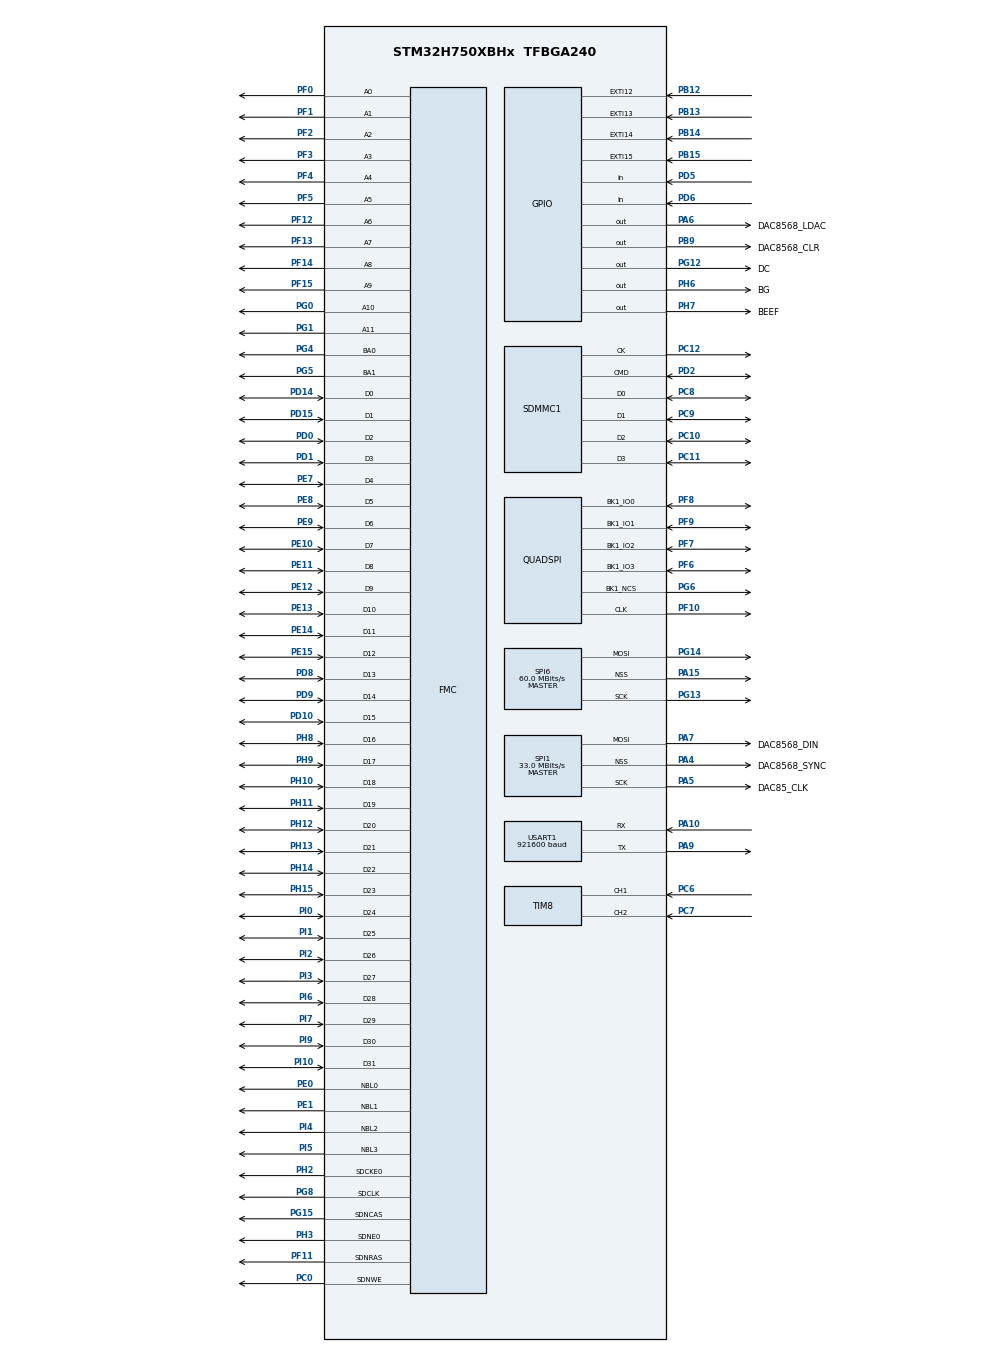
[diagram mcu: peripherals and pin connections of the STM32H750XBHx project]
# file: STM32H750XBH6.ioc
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CORTEX_M7.AccessPermission-Cortex_Memory_Protection_Unit_Region0_Settings=MPU_REGION_FULL_ACCESS
CORTEX_M7.AccessPermission-Cortex_Memory_Protection_Unit_Region1_Settings=MPU_REGION_FULL_ACCESS
CORTEX_M7.BaseAddress-Cortex_Memory_Protection_Unit_Region0_Settings=0xC0000000
CORTEX_M7.BaseAddress-Cortex_Memory_Protection_Unit_Region1_Settings=0x24000000
CORTEX_M7.CPU_DCache=Enabled
CORTEX_M7.CPU_ICache=Enabled
CORTEX_M7.Enable-Cortex_Memory_Protection_Unit_Region0_Settings=MPU_REGION_ENABLE
CORTEX_M7.Enable-Cortex_Memory_Protection_Unit_Region1_Settings=MPU_REGION_ENABLE
CORTEX_M7.IsBufferable-Cortex_Memory_Protection_Unit_Region0_Settings=MPU_ACCESS_NOT_BUFFERABLE
CORTEX_M7.IsBufferable-Cortex_Memory_Protection_Unit_Region1_Settings=MPU_ACCESS_BUFFERABLE
CORTEX_M7.IsCacheable-Cortex_Memory_Protection_Unit_Region0_Settings=MPU_ACCESS_CACHEABLE
CORTEX_M7.IsCacheable-Cortex_Memory_Protection_Unit_Region1_Settings=MPU_ACCESS_CACHEABLE
CORTEX_M7.IsShareable-Cortex_Memory_Protection_Unit_Region1_Settings=MPU_ACCESS_SHAREABLE
CORTEX_M7.MPU_Control=MPU_PRIVILEGED_DEFAULT
CORTEX_M7.Size-Cortex_Memory_Protection_Unit_Region0_Settings=MPU_REGION_SIZE_16MB
CORTEX_M7.Size-Cortex_Memory_Protection_Unit_Region1_Settings=MPU_REGION_SIZE_512KB
CORTEX_M7.TypeExtField-Cortex_Memory_Protection_Unit_Region1_Settings=MPU_TEX_LEVEL1
DMA2D.ColorMode=DMA2D_OUTPUT_RGB565
Dma.Request0=USART1_RX
Dma.Request1=USART1_TX
Dma.Request2=SPI1_TX
Dma.SPI1_TX.2.Direction=DMA_MEMORY_TO_PERIPH
Dma.SPI1_TX.2.EventEnable=DISABLE
Dma.SPI1_TX.2.FIFOMode=DMA_FIFOMODE_DISABLE
Dma.SPI1_TX.2.Instance=DMA1_Stream4
Dma.SPI1_TX.2.MemDataAlignment=DMA_MDATAALIGN_WORD
Dma.SPI1_TX.2.MemInc=DMA_MINC_ENABLE
Dma.SPI1_TX.2.Mode=DMA_CIRCULAR
Dma.SPI1_TX.2.PeriphDataAlignment=DMA_PDATAALIGN_WORD
Dma.SPI1_TX.2.PeriphInc=DMA_PINC_DISABLE
Dma.SPI1_TX.2.Polarity=HAL_DMAMUX_REQ_GEN_RISING
Dma.SPI1_TX.2.Priority=DMA_PRIORITY_HIGH
Dma.SPI1_TX.2.RequestNumber=1
Dma.SPI1_TX.2.SignalID=NONE
Dma.SPI1_TX.2.SyncEnable=DISABLE
Dma.SPI1_TX.2.SyncPolarity=HAL_DMAMUX_SYNC_NO_EVENT
Dma.SPI1_TX.2.SyncRequestNumber=1
Dma.SPI1_TX.2.SyncSignalID=NONE
Dma.USART1_RX.0.Direction=DMA_PERIPH_TO_MEMORY
Dma.USART1_RX.0.EventEnable=DISABLE
Dma.USART1_RX.0.FIFOMode=DMA_FIFOMODE_DISABLE
Dma.USART1_RX.0.Instance=DMA1_Stream0
Dma.USART1_RX.0.MemDataAlignment=DMA_MDATAALIGN_BYTE
Dma.USART1_RX.0.MemInc=DMA_MINC_ENABLE
Dma.USART1_RX.0.Mode=DMA_NORMAL
Dma.USART1_RX.0.PeriphDataAlignment=DMA_PDATAALIGN_BYTE
Dma.USART1_RX.0.PeriphInc=DMA_PINC_DISABLE
Dma.USART1_RX.0.Polarity=HAL_DMAMUX_REQ_GEN_RISING
Dma.USART1_RX.0.Priority=DMA_PRIORITY_VERY_HIGH
Dma.USART1_RX.0.RequestNumber=1
Dma.USART1_RX.0.SignalID=NONE
Dma.USART1_RX.0.SyncEnable=DISABLE
Dma.USART1_RX.0.SyncPolarity=HAL_DMAMUX_SYNC_NO_EVENT
Dma.USART1_RX.0.SyncRequestNumber=1
Dma.USART1_RX.0.SyncSignalID=NONE
Dma.USART1_TX.1.Direction=DMA_MEMORY_TO_PERIPH
Dma.USART1_TX.1.EventEnable=DISABLE
Dma.USART1_TX.1.FIFOMode=DMA_FIFOMODE_DISABLE
Dma.USART1_TX.1.Instance=DMA1_Stream1
Dma.USART1_TX.1.MemDataAlignment=DMA_MDATAALIGN_BYTE
Dma.USART1_TX.1.MemInc=DMA_MINC_ENABLE
Dma.USART1_TX.1.Mode=DMA_NORMAL
Dma.USART1_TX.1.PeriphDataAlignment=DMA_PDATAALIGN_BYTE
Dma.USART1_TX.1.PeriphInc=DMA_PINC_DISABLE
Dma.USART1_TX.1.Polarity=HAL_DMAMUX_REQ_GEN_RISING
Dma.USART1_TX.1.Priority=DMA_PRIORITY_VERY_HIGH
Dma.USART1_TX.1.RequestNumber=1
Dma.USART1_TX.1.SignalID=NONE
Dma.USART1_TX.1.SyncEnable=DISABLE
Dma.USART1_TX.1.SyncPolarity=HAL_DMAMUX_SYNC_NO_EVENT
Dma.USART1_TX.1.SyncRequestNumber=1
Dma.USART1_TX.1.SyncSignalID=NONE
FATFS._CODE_PAGE=437
FATFS._FS_LOCK=16
FATFS._USE_LFN=3
FATFS._VOLUMES=1
FMC.CASLatency1=FMC_SDRAM_CAS_LATENCY_3
FMC.ColumnBitsNumber1=FMC_SDRAM_COLUMN_BITS_NUM_8
FMC.ExitSelfRefreshDelay1=7
FMC.LoadToActiveDelay1=2
FMC.RCDDelay1=2
FMC.RPDelay1=2
FMC.RPDelay2=2
FMC.ReadBurst1=FMC_SDRAM_RBURST_ENABLE
FMC.ReadBurst2=FMC_SDRAM_RBURST_ENABLE
FMC.RowCycleDelay1=7
FMC.RowCycleDelay2=7
FMC.SDClockPeriod1=FMC_SDRAM_CLOCK_PERIOD_2
FMC.SDClockPeriod2=FMC_SDRAM_CLOCK_PERIOD_2
FMC.SelfRefreshTime1=4
FMC.WriteRecoveryTime1=3
FREERTOS.Tasks01=LVGL940,24,2048,LVGL_Task,Default,NULL,Dynamic,NULL,NULL;LED,8,128,LED_Task,Default,NULL,Dynamic,NULL,NULL;Main,8,8192,Main_Task,Default,NULL,Dynamic,NULL,NULL
FREERTOS.configTOTAL_HEAP_SIZE=102400
FREERTOS.configUSE_TICK_HOOK=1
Mcu.Family=STM32H7
Mcu.Name=STM32H750XBHx
Mcu.Package=TFBGA240
Mdma.MDMA_Channel0.Request0=SDMMC1_END_DATA
Mdma.MDMA_Channel0.RequestsNb=1
Mdma.MDMA_Channel0.SDMMC1_END_DATA.0.BlockCount=0
Mdma.MDMA_Channel0.SDMMC1_END_DATA.0.BlockDataLength=0
Mdma.MDMA_Channel0.SDMMC1_END_DATA.0.BufferTransferLength=1
Mdma.MDMA_Channel0.SDMMC1_END_DATA.0.CircularMode=MDMA_LINEAR_LIST
Mdma.MDMA_Channel0.SDMMC1_END_DATA.0.DataAlignment=MDMA_DATAALIGN_PACKENABLE
Mdma.MDMA_Channel0.SDMMC1_END_DATA.0.DestBlockAddressOffset=0
Mdma.MDMA_Channel0.SDMMC1_END_DATA.0.DestBurst=MDMA_DEST_BURST_SINGLE
Mdma.MDMA_Channel0.SDMMC1_END_DATA.0.DestDataSize=MDMA_DEST_DATASIZE_BYTE
Mdma.MDMA_Channel0.SDMMC1_END_DATA.0.DestinationInc=MDMA_DEST_INC_BYTE
Mdma.MDMA_Channel0.SDMMC1_END_DATA.0.DstAddress=0
Mdma.MDMA_Channel0.SDMMC1_END_DATA.0.Endianness=MDMA_LITTLE_ENDIANNESS_PRESERVE
Mdma.MDMA_Channel0.SDMMC1_END_DATA.0.Instance=MDMA_Channel0
Mdma.MDMA_Channel0.SDMMC1_END_DATA.0.MaskAddress=0
Mdma.MDMA_Channel0.SDMMC1_END_DATA.0.MaskData=0
Mdma.MDMA_Channel0.SDMMC1_END_DATA.0.Priority=MDMA_PRIORITY_LOW
Mdma.MDMA_Channel0.SDMMC1_END_DATA.0.Rank=First
Mdma.MDMA_Channel0.SDMMC1_END_DATA.0.SourceBlockAddressOffset=0
Mdma.MDMA_Channel0.SDMMC1_END_DATA.0.SourceBurst=MDMA_SOURCE_BURST_SINGLE
Mdma.MDMA_Channel0.SDMMC1_END_DATA.0.SourceDataSize=MDMA_SRC_DATASIZE_BYTE
Mdma.MDMA_Channel0.SDMMC1_END_DATA.0.SourceInc=MDMA_SRC_INC_BYTE
Mdma.MDMA_Channel0.SDMMC1_END_DATA.0.SrcAddress=0
Mdma.MDMA_Channel0.SDMMC1_END_DATA.0.TransferTriggerMode=MDMA_BUFFER_TRANSFER
Mdma.MDMA_Channel1.QUADSPI_FIFO_TH.0.BlockCount=0
Mdma.MDMA_Channel1.QUADSPI_FIFO_TH.0.BlockDataLength=0
Mdma.MDMA_Channel1.QUADSPI_FIFO_TH.0.BufferTransferLength=128
Mdma.MDMA_Channel1.QUADSPI_FIFO_TH.0.CircularMode=MDMA_LINEAR_LIST
Mdma.MDMA_Channel1.QUADSPI_FIFO_TH.0.DataAlignment=MDMA_DATAALIGN_PACKENABLE
Mdma.MDMA_Channel1.QUADSPI_FIFO_TH.0.DestBlockAddressOffset=0
Mdma.MDMA_Channel1.QUADSPI_FIFO_TH.0.DestBurst=MDMA_DEST_BURST_SINGLE
Mdma.MDMA_Channel1.QUADSPI_FIFO_TH.0.DestDataSize=MDMA_DEST_DATASIZE_WORD
Mdma.MDMA_Channel1.QUADSPI_FIFO_TH.0.DestinationInc=MDMA_DEST_INC_DISABLE
Mdma.MDMA_Channel1.QUADSPI_FIFO_TH.0.DstAddress=0
Mdma.MDMA_Channel1.QUADSPI_FIFO_TH.0.Endianness=MDMA_LITTLE_ENDIANNESS_PRESERVE
Mdma.MDMA_Channel1.QUADSPI_FIFO_TH.0.Instance=MDMA_Channel1
Mdma.MDMA_Channel1.QUADSPI_FIFO_TH.0.MaskAddress=0
Mdma.MDMA_Channel1.QUADSPI_FIFO_TH.0.MaskData=0
Mdma.MDMA_Channel1.QUADSPI_FIFO_TH.0.Priority=MDMA_PRIORITY_VERY_HIGH
Mdma.MDMA_Channel1.QUADSPI_FIFO_TH.0.Rank=First
Mdma.MDMA_Channel1.QUADSPI_FIFO_TH.0.SourceBlockAddressOffset=0
Mdma.MDMA_Channel1.QUADSPI_FIFO_TH.0.SourceBurst=MDMA_SOURCE_BURST_SINGLE
Mdma.MDMA_Channel1.QUADSPI_FIFO_TH.0.SourceDataSize=MDMA_SRC_DATASIZE_WORD
Mdma.MDMA_Channel1.QUADSPI_FIFO_TH.0.SourceInc=MDMA_SRC_INC_WORD
Mdma.MDMA_Channel1.QUADSPI_FIFO_TH.0.SrcAddress=0
Mdma.MDMA_Channel1.QUADSPI_FIFO_TH.0.TransferTriggerMode=MDMA_BUFFER_TRANSFER
Mdma.MDMA_Channel1.Request0=QUADSPI_FIFO_TH
Mdma.MDMA_Channel1.RequestsNb=1
Mdma.RequestSet0=MDMA_Channel0
Mdma.RequestSet1=MDMA_Channel1
Mdma.RequestSetsNb=2
NVIC.DMA1_Stream0_IRQn=true\:5\:0\:false\:false\:true\:true\:false\:true\:true
NVIC.DMA1_Stream1_IRQn=true\:5\:0\:false\:false\:true\:true\:false\:true\:true
NVIC.DMA1_Stream4_IRQn=true\:5\:0\:false\:false\:true\:true\:false\:true\:true
NVIC.EXTI15_10_IRQn=true\:7\:0\:true\:false\:true\:true\:true\:true\:true
NVIC.MDMA_IRQn=true\:6\:0\:true\:false\:true\:true\:false\:true\:true
NVIC.PriorityGroup=NVIC_PRIORITYGROUP_4
NVIC.QUADSPI_IRQn=true\:5\:0\:false\:false\:true\:true\:true\:true\:true
NVIC.SDMMC1_IRQn=true\:6\:0\:true\:false\:true\:true\:true\:true\:true
NVIC.SPI1_IRQn=true\:5\:0\:false\:false\:true\:true\:false\:true\:true
NVIC.TIM17_IRQn=true\:15\:0\:false\:false\:true\:false\:false\:true\:true
NVIC.TIM3_IRQn=true\:5\:0\:false\:false\:true\:true\:true\:true\:true
NVIC.TIM8_BRK_TIM12_IRQn=true\:5\:0\:false\:false\:true\:true\:true\:true\:true
NVIC.TimeBase=TIM17_IRQn
NVIC.TimeBaseIP=TIM17
NVIC.USART1_IRQn=true\:5\:0\:false\:false\:true\:true\:true\:true\:true
PA10.GPIO_Speed=GPIO_SPEED_FREQ_VERY_HIGH
PA10.Mode=Asynchronous
PA10.PinAttribute=Free
PA10.Signal=USART1_RX
PA13\ (JTMS/SWDIO).Mode=Serial_Wire
PA13\ (JTMS/SWDIO).Signal=DEBUG_JTMS-SWDIO
PA14\ (JTCK/SWCLK).Mode=Serial_Wire
PA14\ (JTCK/SWCLK).PinAttribute=Free
PA14\ (JTCK/SWCLK).Signal=DEBUG_JTCK-SWCLK
PA15\ (JTDI).GPIO_Speed=GPIO_SPEED_FREQ_VERY_HIGH
PA15\ (JTDI).Mode=NSS_Signal_Hard_Output
PA15\ (JTDI).Signal=SPI6_NSS
PA4.GPIO_Label=DAC8568_SYNC
PA4.GPIO_Speed=GPIO_SPEED_FREQ_VERY_HIGH
PA4.Mode=NSS_Signal_Hard_Output
PA4.Signal=SPI1_NSS
PA5.GPIO_Label=DAC85_CLK
PA5.GPIO_Speed=GPIO_SPEED_FREQ_LOW
PA5.Mode=TX_Only_Simplex_Unidirect_Master
PA5.PinAttribute=Free
PA5.Signal=SPI1_SCK
PA6.GPIO_Label=DAC8568_LDAC
PA6.GPIO_Speed=GPIO_SPEED_FREQ_VERY_HIGH
PA6.PinAttribute=Free
PA6.PinState=GPIO_PIN_SET
PA6.Signal=GPIO_Output
PA7.GPIO_Label=DAC8568_DIN
PA7.GPIO_Speed=GPIO_SPEED_FREQ_LOW
PA7.Mode=TX_Only_Simplex_Unidirect_Master
PA7.PinAttribute=Free
PA7.Signal=SPI1_MOSI
PA9.GPIO_Speed=GPIO_SPEED_FREQ_VERY_HIGH
PA9.Mode=Asynchronous
PA9.PinAttribute=Free
PA9.Signal=USART1_TX
PB12.GPIO_ModeDefaultEXTI=GPIO_MODE_IT_FALLING
PB12.GPIO_PuPd=GPIO_PULLUP
PB12.PinAttribute=Free
PB12.Signal=GPXTI12
PB13.GPIO_ModeDefaultEXTI=GPIO_MODE_IT_FALLING
PB13.GPIO_PuPd=GPIO_PULLUP
PB13.Signal=GPXTI13
PB14.GPIO_ModeDefaultEXTI=GPIO_MODE_IT_FALLING
PB14.GPIO_PuPd=GPIO_PULLUP
PB14.Signal=GPXTI14
PB15.GPIO_ModeDefaultEXTI=GPIO_MODE_IT_FALLING
PB15.GPIO_PuPd=GPIO_PULLUP
PB15.PinAttribute=Free
PB15.Signal=GPXTI15
PB9.GPIO_Label=DAC8568_CLR
PB9.GPIO_Speed=GPIO_SPEED_FREQ_LOW
PB9.PinState=GPIO_PIN_SET
PB9.Signal=GPIO_Output
PC0.Signal=FMC_SDNWE
PC10.GPIO_PuPd=GPIO_NOPULL
PC10.Mode=SD_4_bits_Wide_bus
PC10.Signal=SDMMC1_D2
PC11.GPIO_PuPd=GPIO_NOPULL
PC11.Mode=SD_4_bits_Wide_bus
PC11.PinAttribute=Free
PC11.Signal=SDMMC1_D3
PC12.GPIO_PuPd=GPIO_NOPULL
PC12.Mode=SD_4_bits_Wide_bus
PC12.Signal=SDMMC1_CK
PC14-OSC32_IN\ (OSC32_IN).Mode=LSE-External-Oscillator
PC14-OSC32_IN\ (OSC32_IN).Signal=RCC_OSC32_IN
PC15-OSC32_OUT\ (OSC32_OUT).Mode=LSE-External-Oscillator
PC15-OSC32_OUT\ (OSC32_OUT).Signal=RCC_OSC32_OUT
PC6.Signal=S_TIM8_CH1
PC7.Signal=S_TIM8_CH2
PC8.GPIO_PuPd=GPIO_NOPULL
PC8.Mode=SD_4_bits_Wide_bus
PC8.PinAttribute=Free
PC8.Signal=SDMMC1_D0
PC9.GPIO_PuPd=GPIO_NOPULL
PC9.Mode=SD_4_bits_Wide_bus
PC9.PinAttribute=Free
PC9.Signal=SDMMC1_D1
PD0.PinAttribute=Free
PD0.Signal=FMC_D2_DA2
PD1.PinAttribute=Free
PD1.Signal=FMC_D3_DA3
PD10.Signal=FMC_D15_DA15
PD14.Signal=FMC_D0_DA0
PD15.Signal=FMC_D1_DA1
PD2.GPIO_PuPd=GPIO_NOPULL
PD2.Mode=SD_4_bits_Wide_bus
PD2.PinAttribute=Free
PD2.Signal=SDMMC1_CMD
PD5.GPIO_Speed=GPIO_SPEED_FREQ_VERY_HIGH
PD5.Signal=GPIO_Input
PD6.GPIO_Speed=GPIO_SPEED_FREQ_VERY_HIGH
PD6.PinAttribute=Free
PD6.Signal=GPIO_Input
PD8.Signal=FMC_D13_DA13
PD9.Signal=FMC_D14_DA14
PE0.Signal=FMC_NBL0
PE1.Signal=FMC_NBL1
PE10.Signal=FMC_D7_DA7
PE11.Signal=FMC_D8_DA8
PE12.PinAttribute=Free
PE12.Signal=FMC_D9_DA9
PE13.PinAttribute=Free
PE13.Signal=FMC_D10_DA10
PE14.Signal=FMC_D11_DA11
PE15.PinAttribute=Free
PE15.Signal=FMC_D12_DA12
PE7.Signal=FMC_D4_DA4
PE8.PinAttribute=Free
PE8.Signal=FMC_D5_DA5
PE9.Signal=FMC_D6_DA6
PF0.Signal=FMC_A0
PF1.Signal=FMC_A1
PF10.GPIO_Speed=GPIO_SPEED_FREQ_VERY_HIGH
PF10.Mode=Single Bank 1
PF10.Signal=QUADSPI_CLK
PF11.PinAttribute=Free
PF11.Signal=FMC_SDNRAS
PF12.PinAttribute=Free
PF12.Signal=FMC_A6
PF13.Signal=FMC_A7
PF14.Signal=FMC_A8
PF15.PinAttribute=Free
PF15.Signal=FMC_A9
PF2.Signal=FMC_A2
PF3.Signal=FMC_A3
PF4.Signal=FMC_A4
PF5.Signal=FMC_A5
PF6.GPIO_Speed=GPIO_SPEED_FREQ_VERY_HIGH
PF6.Mode=Single Bank 1
PF6.Signal=QUADSPI_BK1_IO3
PF7.GPIO_Speed=GPIO_SPEED_FREQ_VERY_HIGH
PF7.Mode=Single Bank 1
PF7.Signal=QUADSPI_BK1_IO2
PF8.GPIO_Speed=GPIO_SPEED_FREQ_VERY_HIGH
PF8.Mode=Single Bank 1
PF8.Signal=QUADSPI_BK1_IO0
PF9.GPIO_Speed=GPIO_SPEED_FREQ_VERY_HIGH
PF9.Mode=Single Bank 1
PF9.Signal=QUADSPI_BK1_IO1
PG0.PinAttribute=Free
PG0.Signal=FMC_A10
PG1.Signal=FMC_A11
PG12.GPIO_Label=DC
PG12.GPIO_Speed=GPIO_SPEED_FREQ_VERY_HIGH
PG12.Signal=GPIO_Output
PG13.GPIO_Speed=GPIO_SPEED_FREQ_VERY_HIGH
PG13.Mode=TX_Only_Simplex_Unidirect_Master
PG13.PinAttribute=Free
PG13.Signal=SPI6_SCK
PG14.GPIO_Speed=GPIO_SPEED_FREQ_VERY_HIGH
PG14.Mode=TX_Only_Simplex_Unidirect_Master
PG14.Signal=SPI6_MOSI
PG15.Signal=FMC_SDNCAS
PG4.Signal=FMC_A14_BA0
PG5.Signal=FMC_A15_BA1
PG6.GPIO_Speed=GPIO_SPEED_FREQ_VERY_HIGH
PG6.Mode=Single Bank 1
PG6.Signal=QUADSPI_BK1_NCS
PG8.Signal=FMC_SDCLK
PH0-OSC_IN\ (PH0).Mode=HSE-External-Oscillator
PH0-OSC_IN\ (PH0).Signal=RCC_OSC_IN
PH1-OSC_OUT\ (PH1).Mode=HSE-External-Oscillator
PH1-OSC_OUT\ (PH1).Signal=RCC_OSC_OUT
PH10.Signal=FMC_D18
PH11.Signal=FMC_D19
PH12.PinAttribute=Free
PH12.Signal=FMC_D20
PH13.PinAttribute=Free
PH13.Signal=FMC_D21
PH14.Signal=FMC_D22
PH15.Signal=FMC_D23
PH2.Mode=SdramChipSelect1_1
PH2.Signal=FMC_SDCKE0
PH3.Mode=SdramChipSelect1_1
PH3.Signal=FMC_SDNE0
PH6.GPIO_Label=BG
PH6.GPIO_Speed=GPIO_SPEED_FREQ_VERY_HIGH
PH6.PinAttribute=Free
PH6.PinState=GPIO_PIN_SET
PH6.Signal=GPIO_Output
PH7.GPIO_Label=BEEF
PH7.GPIO_Speed=GPIO_SPEED_FREQ_VERY_HIGH
PH7.PinState=GPIO_PIN_SET
PH7.Signal=GPIO_Output
PH8.PinAttribute=Free
PH8.Signal=FMC_D16
PH9.PinAttribute=Free
PH9.Signal=FMC_D17
PI0.Signal=FMC_D24
PI1.Signal=FMC_D25
PI10.Signal=FMC_D31
PI2.Signal=FMC_D26
PI3.Signal=FMC_D27
PI4.Signal=FMC_NBL2
PI5.PinAttribute=Free
PI5.Signal=FMC_NBL3
PI6.Signal=FMC_D28
PI7.Signal=FMC_D29
PI9.PinAttribute=Free
PI9.Signal=FMC_D30
ProjectManager.HeapSize=0x2000
ProjectManager.StackSize=0x2000
ProjectManager.TargetToolchain=MDK-ARM V5.32
QUADSPI.ClockMode=QSPI_CLOCK_MODE_3
QUADSPI.ClockPrescaler=1
QUADSPI.FifoThreshold=32
QUADSPI.FlashSize=24
QUADSPI.SampleShifting=QSPI_SAMPLE_SHIFTING_HALFCYCLE
RCC.ADCFreq_Value=132000000
RCC.APB1Freq_Value=120000000
RCC.APB2Freq_Value=120000000
RCC.APB3Freq_Value=120000000
RCC.APB4Freq_Value=120000000
RCC.CortexFreq_Value=480000000
RCC.D1PPRE=RCC_APB3_DIV2
RCC.D2PPRE1=RCC_APB1_DIV2
RCC.D2PPRE2=RCC_APB2_DIV2
RCC.D3PPRE=RCC_APB4_DIV2
RCC.DIVM1=4
RCC.DIVM3=8
RCC.DIVN1=60
RCC.DIVN2=132
RCC.DIVN3=50
RCC.DIVQ1=4
RCC.DIVQ3=8
RCC.DIVR3=8
RCC.HCLKFreq_Value=240000000
RCC.HPRE=RCC_HCLK_DIV2
RCC.PLL2FRACN=0
RCC.PLL3FRACN=0
RCC.PLLFRACN=0
RCC.RTCClockSelection=RCC_RTCCLKSOURCE_LSE
RCC.SPI123CLockSelection=RCC_SPI123CLKSOURCE_PLL2
RCC.SYSCLKFreq_VALUE=480000000
RCC.SYSCLKSource=RCC_SYSCLKSOURCE_PLLCLK
RCC.USBFreq_Value=240000000
SDMMC1.ClockDiv=0
SH.FMC_A0.0=FMC_A0,12b-sda1
SH.FMC_A1.0=FMC_A1,12b-sda1
SH.FMC_A10.0=FMC_A10,12b-sda1
SH.FMC_A11.0=FMC_A11,12b-sda1
SH.FMC_A14_BA0.0=FMC_BA0,FourSdramBanks1
SH.FMC_A15_BA1.0=FMC_BA1,FourSdramBanks1
SH.FMC_A2.0=FMC_A2,12b-sda1
SH.FMC_A3.0=FMC_A3,12b-sda1
SH.FMC_A4.0=FMC_A4,12b-sda1
SH.FMC_A5.0=FMC_A5,12b-sda1
SH.FMC_A6.0=FMC_A6,12b-sda1
SH.FMC_A7.0=FMC_A7,12b-sda1
SH.FMC_A8.0=FMC_A8,12b-sda1
SH.FMC_A9.0=FMC_A9,12b-sda1
SH.FMC_D0_DA0.0=FMC_D0,sd-32b-d1
SH.FMC_D10_DA10.0=FMC_D10,sd-32b-d1
SH.FMC_D11_DA11.0=FMC_D11,sd-32b-d1
SH.FMC_D12_DA12.0=FMC_D12,sd-32b-d1
SH.FMC_D13_DA13.0=FMC_D13,sd-32b-d1
SH.FMC_D14_DA14.0=FMC_D14,sd-32b-d1
SH.FMC_D15_DA15.0=FMC_D15,sd-32b-d1
SH.FMC_D16.0=FMC_D16,sd-32b-d1
SH.FMC_D17.0=FMC_D17,sd-32b-d1
SH.FMC_D18.0=FMC_D18,sd-32b-d1
SH.FMC_D19.0=FMC_D19,sd-32b-d1
SH.FMC_D1_DA1.0=FMC_D1,sd-32b-d1
SH.FMC_D20.0=FMC_D20,sd-32b-d1
SH.FMC_D21.0=FMC_D21,sd-32b-d1
SH.FMC_D22.0=FMC_D22,sd-32b-d1
SH.FMC_D23.0=FMC_D23,sd-32b-d1
SH.FMC_D24.0=FMC_D24,sd-32b-d1
SH.FMC_D25.0=FMC_D25,sd-32b-d1
SH.FMC_D26.0=FMC_D26,sd-32b-d1
SH.FMC_D27.0=FMC_D27,sd-32b-d1
SH.FMC_D28.0=FMC_D28,sd-32b-d1
SH.FMC_D29.0=FMC_D29,sd-32b-d1
SH.FMC_D2_DA2.0=FMC_D2,sd-32b-d1
SH.FMC_D30.0=FMC_D30,sd-32b-d1
SH.FMC_D31.0=FMC_D31,sd-32b-d1
SH.FMC_D3_DA3.0=FMC_D3,sd-32b-d1
SH.FMC_D4_DA4.0=FMC_D4,sd-32b-d1
SH.FMC_D5_DA5.0=FMC_D5,sd-32b-d1
SH.FMC_D6_DA6.0=FMC_D6,sd-32b-d1
SH.FMC_D7_DA7.0=FMC_D7,sd-32b-d1
SH.FMC_D8_DA8.0=FMC_D8,sd-32b-d1
SH.FMC_D9_DA9.0=FMC_D9,sd-32b-d1
SH.FMC_NBL0.0=FMC_NBL0,Sd4ByteEnable1
SH.FMC_NBL1.0=FMC_NBL1,Sd4ByteEnable1
SH.FMC_NBL2.0=FMC_NBL2,Sd4ByteEnable1
SH.FMC_NBL3.0=FMC_NBL3,Sd4ByteEnable1
SH.FMC_SDCLK.0=FMC_SDCLK,12b-sda1
SH.FMC_SDNCAS.0=FMC_SDNCAS,12b-sda1
SH.FMC_SDNRAS.0=FMC_SDNRAS,12b-sda1
SH.FMC_SDNWE.0=FMC_SDNWE,12b-sda1
SH.S_TIM8_CH1.0=TIM8_CH1,Encoder_Interface
SH.S_TIM8_CH2.0=TIM8_CH2,Encoder_Interface
SPI1.BaudRatePrescaler=SPI_BAUDRATEPRESCALER_4
SPI1.CLKPhase=SPI_PHASE_2EDGE
SPI1.CalculateBaudRate=33.0 MBits/s
SPI1.DataSize=SPI_DATASIZE_32BIT
SPI1.Direction=SPI_DIRECTION_2LINES_TXONLY
SPI1.MasterInterDataIdleness=SPI_MASTER_INTERDATA_IDLENESS_02CYCLE
SPI1.MasterSSIdleness=SPI_MASTER_SS_IDLENESS_02CYCLE
SPI1.Mode=SPI_MODE_MASTER
SPI1.VirtualNSS=VM_NSSHARD
SPI1.VirtualType=VM_MASTER
SPI6.CalculateBaudRate=60.0 MBits/s
SPI6.DataSize=SPI_DATASIZE_8BIT
SPI6.Direction=SPI_DIRECTION_2LINES_TXONLY
SPI6.FifoThreshold=SPI_FIFO_THRESHOLD_02DATA
SPI6.Mode=SPI_MODE_MASTER
SPI6.VirtualNSS=VM_NSSHARD
SPI6.VirtualType=VM_MASTER
TIM12.Period=1000-1
TIM12.TIM_MasterOutputTrigger=TIM_TRGO_UPDATE
TIM16.Prescaler=240-1
TIM3.Period=10000-1
TIM3.Prescaler=24000-1
TIM8.IC1Filter=0xF
USART1.BaudRate=921600
USART1.VirtualMode-Asynchronous=VM_ASYNC
VP_DMA2D_VS_DMA2D.Mode=DMA2D_Activate
VP_FATFS_VS_SDIO.Mode=SDIO
VP_FREERTOS_VS_CMSIS_V2.Mode=CMSIS_V2
VP_MEMORYMAP_VS_MEMORYMAP.Mode=CurAppReg
VP_RTC_VS_RTC_Activate.Mode=RTC_Enabled
VP_RTC_VS_RTC_Calendar.Mode=RTC_Calendar
VP_SYS_VS_tim17.Mode=TIM17
VP_TIM12_VS_ClockSourceINT.Mode=Internal
VP_TIM16_VS_ClockSourceINT.Mode=Enable_Timer
VP_TIM3_VS_ClockSourceINT.Mode=Internal
board=custom

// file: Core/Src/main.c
/* USER CODE BEGIN Header */
/**
 ******************************************************************************
 * @file           : main.c
 * @brief          : Main program body
 ******************************************************************************
 * @attention
 *
 * Copyright (c) 2024 STMicroelectronics.
 * All rights reserved.
 *
 * This software is licensed under terms that can be found in the LICENSE file
 * in the root directory of this software component.
 * If no LICENSE file comes with this software, it is provided AS-IS.
 *
 ******************************************************************************
 */
/* USER CODE END Header */
#include "main.h"
#include "cmsis_os.h"
#include "dma.h"
#include "dma2d.h"
#include "fatfs.h"
#include "mdma.h"
#include "quadspi.h"
#include "rtc.h"
#include "sdmmc.h"
#include "spi.h"
#include "tim.h"
#include "usart.h"
#include "gpio.h"
#include "fmc.h"

/* USER CODE BEGIN Includes */
#include "led.h"
#include "sdram.h"
#include "lcd_spi_200.h"
#include "DAC8568/dac8568_dma.h"
#include "sd_waveform.h"
#include "lvgl.h"
#include "lv_port_disp.h"
#include "lv_port_indev.h"
// Demo 已移除，使用自定义 EdgeWind UI

#include <string.h>
#include "arm_math.h"
#include <stdio.h>
#include <stdarg.h>
#include "arm_const_structs.h"

#include <stdio.h>

/* USER CODE END Includes */

/* USER CODE BEGIN PV */
osMutexId_t mutex_id; //

const osMutexAttr_t Thread_Mutex_attr = {
    //
    "myThreadMutex",    // human readable mutex name     //
    osMutexPrioInherit, // attr_bits                 //
    NULL,               // memory for control block       //
    0U                  // size for control block        //
};

/* USER CODE END PV */

void SystemClock_Config(void);
static void MPU_Config(void);
void MX_FREERTOS_Init(void);

int main(void)
{

  /* MPU Configuration--------------------------------------------------------*/
  MPU_Config();

  /* Enable the CPU Cache */

  /* Enable I-Cache---------------------------------------------------------*/
  SCB_EnableICache();

  /* Enable D-Cache---------------------------------------------------------*/
  SCB_EnableDCache();

  /* MCU Configuration--------------------------------------------------------*/

  /* Reset of all peripherals, Initializes the Flash interface and the Systick. */
  HAL_Init();

  /* Configure the system clock */
  SystemClock_Config();

  /* Initialize all configured peripherals */
  MX_GPIO_Init();
  MX_MDMA_Init();
  MX_DMA_Init();
  MX_USART1_UART_Init();
  MX_FMC_Init();
  MX_DMA2D_Init();
  MX_TIM3_Init();
  MX_SDMMC1_SD_Init();
  MX_FATFS_Init();
  MX_RTC_Init();
  MX_TIM16_Init();
  MX_QUADSPI_Init();
  MX_SPI1_Init();
  MX_TIM12_Init();
  MX_SPI6_Init();
  MX_TIM8_Init();
  /* USER CODE BEGIN 2 */
  //		Stack_Size      EQU     0x00000400 //
  //		Stack_Size      EQU     0x0000FF00

  /*
   * Fix DAC output spikes during UI key/page switching:
   *
   * - FreeRTOS masks interrupts at and below configLIBRARY_MAX_SYSCALL_INTERRUPT_PRIORITY (5)
   *   when entering critical sections (BASEPRI). CubeMX keeps the SPI1 TX DMA
   *   (DMA1_Stream4_IRQn) and SPI1 IRQ at priority 5 while FreeRTOS is enabled.
   * - The DAC streaming ISR path intentionally overrides those two IRQs to priority 4
   *   at runtime so circular DMA refill is not blocked by RTOS critical sections.
   *   Keep UI EXTI keys at a lower priority.
   *
   * NOTE: DMA1_Stream4/SPI1 callbacks must not call FreeRTOS APIs while priority is 4.
   */
  HAL_NVIC_SetPriority(DMA1_Stream4_IRQn, 4, 0);
  HAL_NVIC_SetPriority(SPI1_IRQn, 4, 0);
  HAL_NVIC_SetPriority(EXTI15_10_IRQn, 7, 0);

  LED_Init();                              //
  SDRAM_Initialization_Sequence(&hsdram1); //
  /* SPI LCD init path (match d1f119 LCD display chain) */
  SPI_LCD_Init();
  LCD_SetBackColor(LCD_BLACK);
  LCD_Clear();
  LCD_SetColor(LCD_GREEN);
  LCD_SetAsciiFont(&ASCII_Font24);
  LCD_DisplayString(8, 8, "SPI LCD BOOT");

  /* Keep LTDC disabled to avoid RGB pipeline interference. */
  HAL_NVIC_DisableIRQ(LTDC_IRQn);
  __HAL_RCC_LTDC_CLK_DISABLE();

  /* DAC8568 streaming output (SPI1+DMA paced by TIM12 TRGO).
   * Wave sync + stream start is done in RTOS (see freertos.c Main_Task). */
  DAC8568_DMA_Init(DAC_SAMPLE_RATE_HZ);
  DAC8568_OutputFixedVoltage(0.0f);
  printf("[DAC] init ok, wave boot handled in RTOS\r\n");

  printf("System Start...\r\n");

  //  FreeRTOS
  /* USER CODE END 2 */

  /* Init scheduler */
  osKernelInitialize();  /* Call init function for freertos objects (in cmsis_os2.c) */
  MX_FREERTOS_Init();

  /* Start scheduler */
  osKernelStart();

  /* We should never get here as control is now taken by the scheduler */

  /* Infinite loop */
  while (1)
  {

  }
}

void SystemClock_Config(void)
{
  RCC_OscInitTypeDef RCC_OscInitStruct = {0};
  RCC_ClkInitTypeDef RCC_ClkInitStruct = {0};

  /** Supply configuration update enable
  */
  HAL_PWREx_ConfigSupply(PWR_LDO_SUPPLY);

  /** Configure the main internal regulator output voltage
  */
  __HAL_PWR_VOLTAGESCALING_CONFIG(PWR_REGULATOR_VOLTAGE_SCALE0);

  while(!__HAL_PWR_GET_FLAG(PWR_FLAG_VOSRDY)) {}

  /** Configure LSE Drive Capability
  */
  HAL_PWR_EnableBkUpAccess();
  __HAL_RCC_LSEDRIVE_CONFIG(RCC_LSEDRIVE_LOW);

  /** Initializes the RCC Oscillators according to the specified parameters
  * in the RCC_OscInitTypeDef structure.
  */
  RCC_OscInitStruct.OscillatorType = RCC_OSCILLATORTYPE_HSI|RCC_OSCILLATORTYPE_LSE;
  RCC_OscInitStruct.LSEState = RCC_LSE_ON;
  RCC_OscInitStruct.HSIState = RCC_HSI_DIV1;
  RCC_OscInitStruct.HSICalibrationValue = RCC_HSICALIBRATION_DEFAULT;
  RCC_OscInitStruct.PLL.PLLState = RCC_PLL_ON;
  RCC_OscInitStruct.PLL.PLLSource = RCC_PLLSOURCE_HSI;
  RCC_OscInitStruct.PLL.PLLM = 4;
  RCC_OscInitStruct.PLL.PLLN = 60;
  RCC_OscInitStruct.PLL.PLLP = 2;
  RCC_OscInitStruct.PLL.PLLQ = 4;
  RCC_OscInitStruct.PLL.PLLR = 2;
  RCC_OscInitStruct.PLL.PLLRGE = RCC_PLL1VCIRANGE_3;
  RCC_OscInitStruct.PLL.PLLVCOSEL = RCC_PLL1VCOWIDE;
  RCC_OscInitStruct.PLL.PLLFRACN = 0;
  if (HAL_RCC_OscConfig(&RCC_OscInitStruct) != HAL_OK)
  {
    Error_Handler();
  }

  /** Initializes the CPU, AHB and APB buses clocks
  */
  RCC_ClkInitStruct.ClockType = RCC_CLOCKTYPE_HCLK|RCC_CLOCKTYPE_SYSCLK
                              |RCC_CLOCKTYPE_PCLK1|RCC_CLOCKTYPE_PCLK2
                              |RCC_CLOCKTYPE_D3PCLK1|RCC_CLOCKTYPE_D1PCLK1;
  RCC_ClkInitStruct.SYSCLKSource = RCC_SYSCLKSOURCE_PLLCLK;
  RCC_ClkInitStruct.SYSCLKDivider = RCC_SYSCLK_DIV1;
  RCC_ClkInitStruct.AHBCLKDivider = RCC_HCLK_DIV2;
  RCC_ClkInitStruct.APB3CLKDivider = RCC_APB3_DIV2;
  RCC_ClkInitStruct.APB1CLKDivider = RCC_APB1_DIV2;
  RCC_ClkInitStruct.APB2CLKDivider = RCC_APB2_DIV2;
  RCC_ClkInitStruct.APB4CLKDivider = RCC_APB4_DIV2;

  if (HAL_RCC_ClockConfig(&RCC_ClkInitStruct, FLASH_LATENCY_4) != HAL_OK)
  {
    Error_Handler();
  }
}

 /* MPU Configuration */

void MPU_Config(void)
{
  MPU_Region_InitTypeDef MPU_InitStruct = {0};

  /* Disables the MPU */
  HAL_MPU_Disable();

  /** Initializes and configures the Region and the memory to be protected
  */
  MPU_InitStruct.Enable = MPU_REGION_ENABLE;
  MPU_InitStruct.Number = MPU_REGION_NUMBER0;
  MPU_InitStruct.BaseAddress = 0xC0000000;
  MPU_InitStruct.Size = MPU_REGION_SIZE_16MB;
  MPU_InitStruct.SubRegionDisable = 0x0;
  MPU_InitStruct.TypeExtField = MPU_TEX_LEVEL0;
  MPU_InitStruct.AccessPermission = MPU_REGION_FULL_ACCESS;
  MPU_InitStruct.DisableExec = MPU_INSTRUCTION_ACCESS_ENABLE;
  MPU_InitStruct.IsShareable = MPU_ACCESS_NOT_SHAREABLE;
  MPU_InitStruct.IsCacheable = MPU_ACCESS_CACHEABLE;
  MPU_InitStruct.IsBufferable = MPU_ACCESS_NOT_BUFFERABLE;

  HAL_MPU_ConfigRegion(&MPU_InitStruct);

  /** Initializes and configures the Region and the memory to be protected
  */
  MPU_InitStruct.Number = MPU_REGION_NUMBER1;
  MPU_InitStruct.BaseAddress = 0x24000000;
  MPU_InitStruct.Size = MPU_REGION_SIZE_512KB;
  MPU_InitStruct.TypeExtField = MPU_TEX_LEVEL1;
  MPU_InitStruct.IsShareable = MPU_ACCESS_SHAREABLE;
  MPU_InitStruct.IsBufferable = MPU_ACCESS_BUFFERABLE;

  HAL_MPU_ConfigRegion(&MPU_InitStruct);
  /* Enables the MPU */
  HAL_MPU_Enable(MPU_PRIVILEGED_DEFAULT);

}

void HAL_TIM_PeriodElapsedCallback(TIM_HandleTypeDef *htim)
{
  if (htim->Instance == TIM17)
  {
    HAL_IncTick();
  }
  /* USER CODE BEGIN Callback 1 */
	if(htim->Instance == TIM3)  //
    {

    }
  if (htim->Instance == TIM2)
  {
    /* TIM2 保留，AD7606 采集逻辑已移除 */
  }
  /* USER CODE END Callback 1 */
}

void Error_Handler(void)
{
  /* USER CODE BEGIN Error_Handler_Debug */
  /* User can add his own implementation to report the HAL error return state */
  DAC8568_DMA_StopAndHold(0.0f);
  if (huart1.Instance != NULL)
  {
    printf("[ERROR] Error_Handler tick=%lu\r\n", (unsigned long)HAL_GetTick());
  }
  __disable_irq();
  while (1)
  {
  }
  /* USER CODE END Error_Handler_Debug */
}

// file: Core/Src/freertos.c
/* USER CODE BEGIN Header */
/**
 ******************************************************************************
 * File Name          : freertos.c
 * Description        : Code for freertos applications
 ******************************************************************************
 * @attention
 *
 * Copyright (c) 2024 STMicroelectronics.
 * All rights reserved.
 *
 * This software is licensed under terms that can be found in the LICENSE file
 * in the root directory of this software component.
 * If no LICENSE file comes with this software, it is provided AS-IS.
 *
 ******************************************************************************
 */
/* USER CODE END Header */

#include "FreeRTOS.h"
#include "task.h"
#include "main.h"
#include "cmsis_os.h"

/* USER CODE BEGIN Includes */
#include "led.h"
#include "stm32h7xx_hal.h"

#include "lvgl.h"
#include "lv_port_disp.h"
#include "lv_port_indev.h"
// Demo 已移除，使用自定义 EdgeWind UI
#include "EdgeWind_UI/edgewind_ui.h"
#include "DAC8568/dac8568_aux4.h"
#include "DAC8568/dac8568_dma.h"
#include "qspi_w25q256.h"
#include "sd_waveform.h"
#include "SD.h"
#include <stdio.h>
#include <string.h>

/* USER CODE END Includes */

/* USER CODE BEGIN PTD */
void HAL_Delay(uint32_t Delay)
{
  if (Delay == 0U)
  {
    return;
  }

  uint32_t tickstart = HAL_GetTick();

  if ((osKernelGetState() == osKernelRunning) && (__get_IPSR() == 0U))
  {
    while ((HAL_GetTick() - tickstart) < Delay)
    {
      osDelay(1);
    }
    return;
  }

  while ((HAL_GetTick() - tickstart) < Delay)
  {
    /* busy wait before scheduler starts or in ISR */
  }
}
/* USER CODE END PTD */

/* USER CODE BEGIN PM */

#ifndef W25Q256_SELFTEST_ENABLE
/* 默认关闭：避免每次上电都擦写外部 Flash。
 * 需要自检时手动改为 1，或通过编译宏覆盖。
 */
#define W25Q256_SELFTEST_ENABLE 0
#endif

#if W25Q256_SELFTEST_ENABLE

#include "qspi_w25q256.h"
#include <string.h>

/* 自检等级：
 * 1: 单扇区擦除 + 单页写入 + 读回校验（最快，推荐长期保留）
 * 2: 增加跨页/跨扇区写入读回（更贴近真实存储使用）
 * 3: 预留（可在后续加入 16MB 边界/更大范围测试）
 */
#ifndef W25Q256_SELFTEST_LEVEL
/* 默认自检等级（仅在 W25Q256_SELFTEST_ENABLE=1 时生效） */
#define W25Q256_SELFTEST_LEVEL 2
#endif

/* 内存映射读取校验（可选）：开启后会将 QSPI 切到 memory-mapped 再 memcpy 读回校验。
 * 注意：memory-mapped 与 cache 行为相关，若你担心影响系统其他读写，保持 0 即可。
 */
#ifndef W25Q256_SELFTEST_USE_MEMORY_MAPPED
#define W25Q256_SELFTEST_USE_MEMORY_MAPPED 0
#endif

#define W25Q256_SELFTEST_ADDR   (0x1FF0000u) /* 32MB Flash 末尾附近，避开常用数据区 */
#define W25Q256_SELFTEST_LEN    (256u)       /* 单页测试 */
#define W25Q256_CROSS_LEN       (512u)       /* 跨页/跨扇区测试长度 */

static int8_t W25Q256_SelfTest_Small(void)
{
  uint8_t tx[W25Q256_SELFTEST_LEN];
  uint8_t rx[W25Q256_SELFTEST_LEN];
  uint32_t id;
  int8_t ret;

  ret = QSPI_W25Qxx_Init();
  id  = QSPI_W25Qxx_ReadID();
  printf("[W25Q256] init ret=%d, JEDEC=0x%06lX\r\n", (int)ret, (unsigned long)id);
  if (ret != QSPI_W25Qxx_OK)
  {
    return ret;
  }

  ret = QSPI_W25Qxx_SectorErase(W25Q256_SELFTEST_ADDR);
  printf("[W25Q256] sector erase @0x%08lX ret=%d\r\n", (unsigned long)W25Q256_SELFTEST_ADDR, (int)ret);
  if (ret != QSPI_W25Qxx_OK)
  {
    return ret;
  }

  for (uint32_t i = 0; i < W25Q256_SELFTEST_LEN; i++)
  {
    tx[i] = (uint8_t)(i ^ 0xA5u);
    rx[i] = 0;
  }

  ret = QSPI_W25Qxx_WritePage(tx, W25Q256_SELFTEST_ADDR, (uint16_t)W25Q256_SELFTEST_LEN);
  printf("[W25Q256] write page ret=%d\r\n", (int)ret);
  if (ret != QSPI_W25Qxx_OK)
  {
    return ret;
  }

  ret = QSPI_W25Qxx_ReadBuffer(rx, W25Q256_SELFTEST_ADDR, W25Q256_SELFTEST_LEN);
  printf("[W25Q256] read back ret=%d\r\n", (int)ret);
  if (ret != QSPI_W25Qxx_OK)
  {
    return ret;
  }

  if (memcmp(tx, rx, W25Q256_SELFTEST_LEN) != 0)
  {
    for (uint32_t i = 0; i < W25Q256_SELFTEST_LEN; i++)
    {
      if (tx[i] != rx[i])
      {
        printf("[W25Q256] verify FAIL @+%lu tx=0x%02X rx=0x%02X\r\n",
               (unsigned long)i, (unsigned int)tx[i], (unsigned int)rx[i]);
        break;
      }
    }
    return (int8_t)W25Qxx_ERROR_TRANSMIT;
  }

  printf("[W25Q256] selftest PASS (erase+program+readback)\r\n");
  return QSPI_W25Qxx_OK;
}

static int8_t W25Q256_SelfTest_CrossPageAndSector(void)
{
  const uint32_t base0 = W25Q256_SELFTEST_ADDR;          /* 4KB 扇区对齐 */
  const uint32_t base1 = W25Q256_SELFTEST_ADDR + 0x1000; /* 下一个 4KB 扇区 */
  const uint32_t start = base0 + 0x0F80u;                /* 故意靠近扇区末尾，触发跨扇区 */
  const uint32_t len   = W25Q256_CROSS_LEN;              /* 512B：跨页且跨扇区 */

  uint8_t tx[W25Q256_CROSS_LEN];
  uint8_t rx[W25Q256_CROSS_LEN];

  printf("[W25Q256] cross-sector test: erase 2 sectors, start=0x%08lX len=%lu\r\n",
         (unsigned long)start, (unsigned long)len);

  int8_t ret = QSPI_W25Qxx_SectorErase(base0);
  printf("[W25Q256] erase sector0 @0x%08lX ret=%d\r\n", (unsigned long)base0, (int)ret);
  if (ret != QSPI_W25Qxx_OK) return ret;

  ret = QSPI_W25Qxx_SectorErase(base1);
  printf("[W25Q256] erase sector1 @0x%08lX ret=%d\r\n", (unsigned long)base1, (int)ret);
  if (ret != QSPI_W25Qxx_OK) return ret;

  /* 擦除校验：读少量数据确认为 0xFF */
  {
    uint8_t blank[64];
    ret = QSPI_W25Qxx_ReadBuffer(blank, base0, sizeof(blank));
    if (ret != QSPI_W25Qxx_OK) return ret;
    for (uint32_t i = 0; i < sizeof(blank); i++)
    {
      if (blank[i] != 0xFFu)
      {
        printf("[W25Q256] erase verify FAIL sector0 @+%lu =0x%02X\r\n",
               (unsigned long)i, (unsigned int)blank[i]);
        return (int8_t)W25Qxx_ERROR_Erase;
      }
    }

    ret = QSPI_W25Qxx_ReadBuffer(blank, base1, sizeof(blank));
    if (ret != QSPI_W25Qxx_OK) return ret;
    for (uint32_t i = 0; i < sizeof(blank); i++)
    {
      if (blank[i] != 0xFFu)
      {
        printf("[W25Q256] erase verify FAIL sector1 @+%lu =0x%02X\r\n",
               (unsigned long)i, (unsigned int)blank[i]);
        return (int8_t)W25Qxx_ERROR_Erase;
      }
    }
    printf("[W25Q256] erase verify PASS (both sectors blank)\r\n");
  }

  for (uint32_t i = 0; i < len; i++)
  {
    tx[i] = (uint8_t)((i * 37u) ^ 0x5Au);
    rx[i] = 0;
  }

  ret = QSPI_W25Qxx_WriteBuffer(tx, start, len);
  printf("[W25Q256] write buffer (cross) ret=%d\r\n", (int)ret);
  if (ret != QSPI_W25Qxx_OK) return ret;

  ret = QSPI_W25Qxx_ReadBuffer(rx, start, len);
  printf("[W25Q256] read buffer (cross) ret=%d\r\n", (int)ret);
  if (ret != QSPI_W25Qxx_OK) return ret;

  if (memcmp(tx, rx, len) != 0)
  {
    for (uint32_t i = 0; i < len; i++)
    {
      if (tx[i] != rx[i])
      {
        printf("[W25Q256] cross verify FAIL @+%lu tx=0x%02X rx=0x%02X\r\n",
               (unsigned long)i, (unsigned int)tx[i], (unsigned int)rx[i]);
        break;
      }
    }
    return (int8_t)W25Qxx_ERROR_TRANSMIT;
  }

#if W25Q256_SELFTEST_USE_MEMORY_MAPPED
  ret = QSPI_W25Qxx_MemoryMappedMode();
  printf("[W25Q256] enter memory-mapped ret=%d\r\n", (int)ret);
  if (ret == QSPI_W25Qxx_OK)
  {
    uint8_t mm[W25Q256_CROSS_LEN];
    memcpy(mm, (uint8_t *)0x90000000u + start, len);
    if (memcmp(tx, mm, len) != 0)
    {
      printf("[W25Q256] memory-mapped verify FAIL\r\n");
      return (int8_t)W25Qxx_ERROR_TRANSMIT;
    }
    printf("[W25Q256] memory-mapped verify PASS\r\n");
  }
#endif

  printf("[W25Q256] cross-sector test PASS\r\n");
  return QSPI_W25Qxx_OK;
}

#endif /* W25Q256_SELFTEST_ENABLE */

/* USER CODE END PM */

/* USER CODE BEGIN Variables */

/* === DAC waveform partitions: 4MB reserved + 7 x 4MB waves === */
#define DAC_WAVE_PART_COUNT SD_DAC_QSPI_PARTITION_COUNT
#define DAC_FAULT_COUNT 6u
#define DAC_FAULT_CMD_NONE    0u
#define DAC_FAULT_CMD_TRIGGER 1u
#define DAC_FAULT_CMD_STOP    2u
#define DAC_FAULT_CMD_QUEUE_LEN 8u
#define DAC_WAVE_ALL_PART_MASK ((uint32_t)((1u << DAC_WAVE_PART_COUNT) - 1u))

typedef struct {
  uint8_t type;
  uint8_t fault_id_0_5;
  uint16_t reserved;
  uint32_t duration_s;
} DacFaultCommand_t;

static SD_DacWaveInfo_t s_dac_wave_info[DAC_WAVE_PART_COUNT];
static uint32_t s_dac_wave_ready_mask = 0u;    /* bit i => partition i header ok */
static uint32_t s_dac_wave_sd_sync_mask = 0u;  /* bit i => partition i synced from SD this boot */
static volatile uint8_t s_dac_wave_boot_sync_done = 0u;
static volatile uint8_t s_dac_stream_started = 0u;

/* Fault burst runtime state (read by UI via DAC_FaultBurst_GetUiState). */
static volatile uint8_t s_fault_active_id_0_5 = 0xFFu; /* 0xFF => normal */
static volatile TickType_t s_fault_end_tick = 0;
static volatile uint32_t s_fault_remaining_s = 0u;
static DacFaultCommand_t s_fault_cmd_queue[DAC_FAULT_CMD_QUEUE_LEN];
static volatile uint8_t s_fault_cmd_head = 0u;
static volatile uint8_t s_fault_cmd_tail = 0u;
static volatile uint8_t s_fault_cmd_count = 0u;

/*
 * Canonical cross-project order:
 * E01 ac_coupling, E02 insulation, E03 cap_aging,
 * E04 igbt_fault, E05 bus_ground, E06 pwm_abnormal.
 */
static const uint8_t s_dac_fault_partition_by_id[DAC_FAULT_COUNT] = {
  SD_DAC_WAVE_PART_AC_COUPLING,
  SD_DAC_WAVE_PART_INSULATION,
  SD_DAC_WAVE_PART_CAP_AGING,
  SD_DAC_WAVE_PART_IGBT_FAULT,
  SD_DAC_WAVE_PART_BUS_GROUND,
  SD_DAC_WAVE_PART_PWM_ABNORMAL,
};

static const char * const s_dac_fault_ai_code_by_id[DAC_FAULT_COUNT] = {
  "E01",
  "E02",
  "E03",
  "E04",
  "E05",
  "E06",
};

static const char * const s_dac_wave_ai_code_by_part[DAC_WAVE_PART_COUNT] = {
  "E00",
  "E01",
  "E02",
  "E03",
  "E04",
  "E05",
  "E06",
};

static const char * const s_dac_wave_sd_paths[DAC_WAVE_PART_COUNT] = {
  DAC_WAVE_SD_PATH_NORMAL,
  DAC_WAVE_SD_PATH_AC_COUPLING,
  DAC_WAVE_SD_PATH_INSULATION,
  DAC_WAVE_SD_PATH_CAP_AGING,
  DAC_WAVE_SD_PATH_IGBT_FAULT,
  DAC_WAVE_SD_PATH_BUS_GROUND,
  DAC_WAVE_SD_PATH_PWM_ABNORMAL,
};

/* USER CODE END Variables */
/* Definitions for LVGL940 */
osThreadId_t LVGL940Handle;
const osThreadAttr_t LVGL940_attributes = {
  .name = "LVGL940",
  .stack_size = 2048 * 4,
  .priority = (osPriority_t) osPriorityNormal,
};
/* Definitions for LED */
osThreadId_t LEDHandle;
const osThreadAttr_t LED_attributes = {
  .name = "LED",
  .stack_size = 128 * 4,
  .priority = (osPriority_t) osPriorityLow,
};
/* Definitions for Main */
osThreadId_t MainHandle;
const osThreadAttr_t Main_attributes = {
  .name = "Main",
  .stack_size = 8192 * 4,
  .priority = (osPriority_t) osPriorityLow,
};

/* USER CODE BEGIN FunctionPrototypes */
extern const osMutexAttr_t Thread_Mutex_attr;

static void dac_fault_burst_service(void);
static bool dac_fault_apply_trigger(uint32_t fault_id_0_5, uint32_t duration_s);
static void dac_fault_apply_stop(void);
static void dac_fault_queue_reset(void);
static uint8_t dac_fault_partition_for_id(uint32_t fault_id_0_5);
static bool dac_fault_post_command(uint8_t cmd_type, uint8_t fault_id_0_5, uint32_t duration_s);
static bool dac_fault_fetch_command(DacFaultCommand_t *cmd_out);
static bool dac_wave_accept_partition(uint32_t index, SD_DacWavePartition_t part, const SD_DacWaveInfo_t *info);
static bool dac_wave_sd_sync_flag_present(void);
static bool dac_wave_wait_for_sd_sync_flag(void);
static void dac_wave_try_clear_sd_sync_flag(void);
static void dac_wave_print_contract(void);
static bool dac_aux4_verify_ready_waves(void);
static int32_t dac_aux4_scale1000(float value);

/* USER CODE END FunctionPrototypes */

void LVGL_Task(void *argument);
void LED_Task(void *argument);
void Main_Task(void *argument);

void MX_FREERTOS_Init(void); /* (MISRA C 2004 rule 8.1) */

/* Hook prototypes */
void vApplicationTickHook(void);

/* USER CODE BEGIN 3 */
void vApplicationTickHook(void)
{
  /* This function will be called by each tick interrupt if
  configUSE_TICK_HOOK is set to 1 in FreeRTOSConfig.h. User code can be
  added here, but the tick hook is called from an interrupt context, so
  code must not attempt to block, and only the interrupt safe FreeRTOS API
  functions can be used (those that end in FromISR()). */

  lv_tick_inc(1);
}

static void RtosFatalHold(const char *reason, const signed char *task_name)
{
  const char *name = (task_name != NULL) ? (const char *)task_name : "-";

  DAC8568_DMA_StopAndHold(0.0f);
  printf("[RTOS FAULT] %s task=%s tick=%lu\r\n",
         reason,
         name,
         (unsigned long)HAL_GetTick());

  taskDISABLE_INTERRUPTS();
  for (;;)
  {
  }
}

static bool dac_wave_sd_sync_flag_present(void)
{
  FILINFO info;
  FRESULT res;

  res = SD_Init();
  if (res != FR_OK) {
    printf("[DAC WAVE] SD sync flag check skipped: SD init=%d path=%s\r\n",
           (int)res,
           DAC_WAVE_SD_SYNC_FLAG_PATH);
    return false;
  }

  memset(&info, 0, sizeof(info));
  res = f_stat(DAC_WAVE_SD_SYNC_FLAG_PATH, &info);
  if (res == FR_OK) {
    printf("[DAC WAVE] SD sync flag found: %s size=%lu\r\n",
           DAC_WAVE_SD_SYNC_FLAG_PATH,
           (unsigned long)info.fsize);
    return true;
  }

  printf("[DAC WAVE] SD sync flag absent: %s stat=%d\r\n",
         DAC_WAVE_SD_SYNC_FLAG_PATH,
         (int)res);
  return false;
}

static bool dac_wave_wait_for_sd_sync_flag(void)
{
  uint32_t elapsed_ms = 0u;
  uint32_t retry_ms = DAC_WAVE_SYNC_FLAG_RETRY_MS;

  if (retry_ms == 0u) {
    retry_ms = 500u;
  }

  printf("[DAC WAVE] waiting SD sync flag up to %lu ms: %s\r\n",
         (unsigned long)DAC_WAVE_SYNC_FLAG_WAIT_MS,
         DAC_WAVE_SD_SYNC_FLAG_PATH);

  for (;;) {
    if (dac_wave_sd_sync_flag_present()) {
      if (elapsed_ms != 0u) {
        printf("[DAC WAVE] SD sync flag became ready after %lu ms\r\n",
               (unsigned long)elapsed_ms);
      }
      return true;
    }

    if (elapsed_ms >= DAC_WAVE_SYNC_FLAG_WAIT_MS) {
      break;
    }

    osDelay(retry_ms);
    elapsed_ms += retry_ms;
  }

  printf("[DAC WAVE] SD sync flag wait timeout after %lu ms, fallback to QSPI\r\n",
         (unsigned long)elapsed_ms);
  return false;
}

static void dac_wave_try_clear_sd_sync_flag(void)
{
#if (DAC_WAVE_CLEAR_SYNC_FLAG_AFTER_SUCCESS != 0)
  FRESULT res = f_unlink(DAC_WAVE_SD_SYNC_FLAG_PATH);
  if ((res == FR_OK) || (res == FR_NO_FILE)) {
    printf("[DAC WAVE] SD sync flag cleared: %s\r\n", DAC_WAVE_SD_SYNC_FLAG_PATH);
  } else {
    printf("[DAC WAVE] SD sync flag clear failed: %s err=%d\r\n",
           DAC_WAVE_SD_SYNC_FLAG_PATH,
           (int)res);
  }
#else
  printf("[DAC WAVE] SD sync flag kept by config: %s\r\n", DAC_WAVE_SD_SYNC_FLAG_PATH);
#endif
}

static void dac_wave_print_contract(void)
{
  printf("[DAC WAVE] canonical order: E00 normal, E01 ac_coupling, E02 insulation, E03 cap_aging, E04 igbt_fault, E05 bus_ground, E06 pwm_abnormal\r\n");
  for (uint32_t i = 0u; i < DAC_WAVE_PART_COUNT; i++) {
    SD_DacWavePartition_t part = (SD_DacWavePartition_t)i;
    printf("[DAC WAVE] contract: part=%lu code=%s name=%s path=%s\r\n",
           (unsigned long)i,
           s_dac_wave_ai_code_by_part[i],
           SD_Wave_GetPartitionName(part),
           s_dac_wave_sd_paths[i]);
  }
}

void vApplicationMallocFailedHook(void)
{
  RtosFatalHold("malloc_failed", NULL);
}

void vApplicationStackOverflowHook(TaskHandle_t xTask, signed char *pcTaskName)
{
  (void)xTask;
  RtosFatalHold("stack_overflow", pcTaskName);
}
/* USER CODE END 3 */

void MX_FREERTOS_Init(void) {

  /* USER CODE BEGIN RTOS_MUTEX */
  /* add mutexes, ... */
  mutex_id = osMutexNew(&Thread_Mutex_attr);
  /* USER CODE END RTOS_MUTEX */

  /* Create the thread(s) */
  /* creation of LVGL940 */
  LVGL940Handle = osThreadNew(LVGL_Task, NULL, &LVGL940_attributes);

  /* creation of LED */
  LEDHandle = osThreadNew(LED_Task, NULL, &LED_attributes);

  /* creation of Main */
  MainHandle = osThreadNew(Main_Task, NULL, &Main_attributes);

}

void LVGL_Task(void *argument)
{
  /* USER CODE BEGIN LVGL_Task */
  uint32_t time;
  UBaseType_t min_hw = (UBaseType_t)0xFFFFFFFFu;
  TickType_t last_log = 0;
  //  // LVGL图形库初始化三件套
  lv_init();            // 初始化LVGL核心库（内存管理、内部变量等）
  lv_port_disp_init();  // 初始化显示驱动接口（配置帧缓冲区、注册刷新回调）
  lv_port_indev_init(); // 初始化输入设备接口（注册触摸屏/编码器驱动）

  /* 初始化 EdgeWind 自定义 UI */
  edgewind_ui_init();
  /* Infinite loop */
  for(;;)
  {

    /* === 临界区开始（保护LVGL操作）=== */
    osMutexAcquire(mutex_id, osWaitForever);

    /* EdgeWind UI 数据刷新 */
    edgewind_ui_refresh();

    /* LVGL 核心处理 */
    lv_task_handler();

    osMutexRelease(mutex_id);
    /* === 临界区结束 === */

    /* 低频监测 LVGL 线程栈水位（观察是否逼近溢出） */
    /* LVGL diagnostics disabled (periodic stack/heap prints). */

    //    /* 周期延时（关键性能参数）*/
    osDelay(LV_DEF_REFR_PERIOD + 1); // 保持屏幕刷新率稳定（典型值30ms≈33FPS）

    // 注意：
    // 1. 延时过短：导致刷新不全（屏幕闪烁）
    // 2. 延时过长：界面响应迟滞
    // 3. LV_DISP_DEF_REFR_PERIOD应与屏显参数匹配（在lv_conf.h中配置）

    // 调试语句（使用时需注意串口输出可能影响实时性）
    // printf("GUI task heartbeat\r\n");
  }
  /* USER CODE END LVGL_Task */
}

void LED_Task(void *argument)
{
  /* USER CODE BEGIN LED_Task */
  /* Infinite loop */
  for(;;)
  {
    LED1_Toggle;
    osDelay(500);
  }
  /* USER CODE END LED_Task */
}

void Main_Task(void *argument)
{
  /* USER CODE BEGIN Main_Task */
  uint8_t stream_enabled = 0u;
  uint8_t do_boot_sync = 0u;
  uint8_t sync_mutex_locked = 0u;
  uint32_t started_sps = 0u;

  memset(s_dac_wave_info, 0, sizeof(s_dac_wave_info));
  s_dac_wave_ready_mask = 0u;
  s_dac_wave_sd_sync_mask = 0u;
  s_dac_wave_boot_sync_done = 0u;
  s_dac_stream_started = 0u;
  s_fault_active_id_0_5 = 0xFFu;
  s_fault_end_tick = 0;
  s_fault_remaining_s = 0u;
  dac_fault_queue_reset();
  dac_wave_print_contract();
  printf("[DAC CFG] version=playback_output_stability_20260701 ref_refresh_ms=%lu spi1_sck_mosi_gpio_speed=LOW spi1_sync_gpio_speed=VERY_HIGH qspi_mmap_dummy=%lu qspi_cmd_dummy=%lu d8cw_channels=4 aux4_source=a4b\r\n",
         (unsigned long)DAC8568_DMA_GetRefRefreshMs(),
         (unsigned long)QSPI_W25Qxx_GetMemoryMappedDummyCycles(),
         (unsigned long)QSPI_W25Qxx_GetCommandReadDummyCycles());

  /* NOTE: FatFs SD driver (FATFS/Target/sd_diskio.c) gates SD_initialize() on
   * osKernelRunning(), so SD mount/sync must happen after scheduler start. */
  if (DAC_WAVE_FORCE_SD_SYNC_ON_BOOT != 0u) {
    do_boot_sync = 1u;
    printf("[DAC WAVE] FORCE SD sync on boot enabled by firmware build\r\n");
  } else if (DAC_WAVE_BOOT_FULL_SYNC != 0u) {
    do_boot_sync = dac_wave_wait_for_sd_sync_flag() ? 1u : 0u;
  }

  if (do_boot_sync != 0u) {
    printf("[DAC] init ok, SD sync flag requested full sync in RTOS\r\n");
    printf("[DAC WAVE] full sync begin: flag=%s partitions=%lu\r\n",
           DAC_WAVE_SD_SYNC_FLAG_PATH,
           (unsigned long)DAC_WAVE_PART_COUNT);
  } else {
    printf("[DAC] init ok, SD sync not requested\r\n");
    printf("[DAC WAVE] boot load begin(from QSPI): partitions=%lu\r\n",
           (unsigned long)DAC_WAVE_PART_COUNT);
  }

  if (do_boot_sync != 0u) {
    uint32_t attempt = 0u;

    if (mutex_id) {
      osMutexAcquire(mutex_id, osWaitForever);
      sync_mutex_locked = 1u;
      printf("[DAC WAVE] locked LVGL mutex during SD->W25Q sync\r\n");
    }

    for (;;) {
      attempt++;
      s_dac_wave_ready_mask = 0u;
      s_dac_wave_sd_sync_mask = 0u;
      memset(s_dac_wave_info, 0, sizeof(s_dac_wave_info));

      printf("[DAC WAVE] full sync attempt %lu begin\r\n", (unsigned long)attempt);

      for (uint32_t i = 0u; i < DAC_WAVE_PART_COUNT; i++) {
        SD_DacWavePartition_t part = (SD_DacWavePartition_t)i;
        SD_DacWaveInfo_t info = {0};
        const char *path = s_dac_wave_sd_paths[i];

        printf("[DAC WAVE] syncing partition %lu/%lu: code=%s part=%s path=%s\r\n",
               (unsigned long)(i + 1u),
               (unsigned long)DAC_WAVE_PART_COUNT,
               s_dac_wave_ai_code_by_part[i],
               SD_Wave_GetPartitionName(part),
               (path != NULL) ? path : "(null)");

        if (SD_Wave_SyncDacToQspiPartition(path, part, &info) &&
            dac_wave_accept_partition(i, part, &info)) {
          s_dac_wave_sd_sync_mask |= (1u << i);
          continue;
        }

        printf("[DAC WAVE] SD sync failed: part=%s path=%s\r\n",
               SD_Wave_GetPartitionName(part),
               (path != NULL) ? path : "(null)");
      }

      printf("[DAC WAVE] full sync attempt %lu done: ready_mask=0x%02lX sd_sync_mask=0x%02lX\r\n",
             (unsigned long)attempt,
             (unsigned long)s_dac_wave_ready_mask,
             (unsigned long)s_dac_wave_sd_sync_mask);

      if ((s_dac_wave_sd_sync_mask & DAC_WAVE_ALL_PART_MASK) == DAC_WAVE_ALL_PART_MASK) {
        break;
      }

      printf("[DAC WAVE] full sync incomplete, system boot is blocked until sync succeeds: synced=0x%02lX expected=0x%02lX\r\n",
             (unsigned long)s_dac_wave_sd_sync_mask,
             (unsigned long)DAC_WAVE_ALL_PART_MASK);
      osDelay(2000);
    }

  } else {
    for (uint32_t i = 0u; i < DAC_WAVE_PART_COUNT; i++) {
      SD_DacWavePartition_t part = (SD_DacWavePartition_t)i;
      SD_DacWaveInfo_t info = {0};

      printf("[DAC WAVE] loading partition %lu/%lu from QSPI: code=%s part=%s\r\n",
             (unsigned long)(i + 1u),
             (unsigned long)DAC_WAVE_PART_COUNT,
             s_dac_wave_ai_code_by_part[i],
             SD_Wave_GetPartitionName(part));

      if (SD_Wave_LoadDacInfoFromQspiPartition(part, &info) &&
          dac_wave_accept_partition(i, part, &info)) {
        printf("[DAC WAVE] load from QSPI ok: code=%s part=%s sps=%lu count=%lu checksum=0x%08lX addr=0x%08lX\r\n",
               s_dac_wave_ai_code_by_part[i],
               SD_Wave_GetPartitionName(part),
               (unsigned long)info.sample_rate_hz,
               (unsigned long)info.sample_count,
               (unsigned long)info.checksum,
               (unsigned long)info.qspi_mmap_addr);
        continue;
      }

      printf("[DAC WAVE] partition not ready: part=%s\r\n", SD_Wave_GetPartitionName(part));
    }
  }

  {
    bool aux4_loaded = false;
    bool aux4_verified = false;

    if (do_boot_sync != 0u) {
      aux4_loaded = DAC8568_Aux4_SyncFromSdToQspi(DAC_WAVE_AUX4_SCHEDULE_PATH);
    }
    if (!aux4_loaded) {
      aux4_loaded = DAC8568_Aux4_LoadFromQspi();
    }
    if (aux4_loaded) {
      aux4_verified = dac_aux4_verify_ready_waves();
    }
    if (!aux4_verified) {
      printf("[AUX4] ready-wave bind not verified, trying SD transient load: %s\r\n",
             DAC_WAVE_AUX4_SCHEDULE_PATH);
      aux4_loaded = DAC8568_Aux4_LoadFromSd(DAC_WAVE_AUX4_SCHEDULE_PATH);
      if (aux4_loaded) {
        aux4_verified = dac_aux4_verify_ready_waves();
      }
    }
    if (!aux4_verified) {
      printf("[AUX4] no verified schedule for current D8CW set, aux4_source=default\r\n");
    }
  }
  if (do_boot_sync != 0u) {
    dac_wave_try_clear_sd_sync_flag();
  }
  if (sync_mutex_locked != 0u) {
    osMutexRelease(mutex_id);
    sync_mutex_locked = 0u;
    printf("[DAC WAVE] unlocked LVGL mutex after SD->W25Q sync\r\n");
  }

  s_dac_wave_boot_sync_done = 1u;
  DAC8568_Aux4_SetActiveFile(DAC_WAVE_SD_PATH_NORMAL, true);
  if (do_boot_sync != 0u) {
    printf("[DAC WAVE] full sync done: ready_mask=0x%02lX sd_sync_mask=0x%02lX\r\n",
           (unsigned long)s_dac_wave_ready_mask,
           (unsigned long)s_dac_wave_sd_sync_mask);
  } else {
    printf("[DAC WAVE] boot load done: ready_mask=0x%02lX\r\n",
           (unsigned long)s_dac_wave_ready_mask);
  }

  if ((s_dac_wave_ready_mask & 0x1u) == 0u) {
    printf("[DAC WAVE] baseline not ready, no output\r\n");
  } else {
#if (DAC_WAVE_REQUIRE_SD_SYNC != 0)
    if ((do_boot_sync != 0u) && ((s_dac_wave_sd_sync_mask & 0x1u) == 0u)) {
      printf("[DAC WAVE] baseline requires SD sync, but SD sync failed; no output\r\n");
    } else
#endif
    {
      SD_DacWaveInfo_t *base = &s_dac_wave_info[0];
      if (DAC8568_DMA_UseQspiWave(base->qspi_mmap_addr, base->sample_count, base->sample_rate_hz) == 0) {
        DAC8568_Aux4_SetActiveFile(DAC_WAVE_SD_PATH_NORMAL, true);
        printf("[DAC WAVE] baseline source=QSPI sps=%lu count=%lu checksum=0x%08lX addr=0x%08lX\r\n",
               (unsigned long)base->sample_rate_hz,
               (unsigned long)base->sample_count,
               (unsigned long)base->checksum,
               (unsigned long)base->qspi_mmap_addr);
        stream_enabled = 1u;
        started_sps = base->sample_rate_hz;
      } else {
        printf("[DAC WAVE] baseline source switch failed, no output\r\n");
      }
    }
  }

  if (stream_enabled != 0u) {
    DAC8568_DMA_Start();
    s_dac_stream_started = 1u;
    printf("[DAC] start sps=%lu\r\n", (unsigned long)started_sps);
  } else {
    DAC8568_OutputFixedVoltage(0.0f);
    printf("[DAC] stream disabled (no waveform output)\r\n");
  }

  TickType_t last_log = xTaskGetTickCount();
  /* Infinite loop */
  for(;;)
  {
    dac_fault_burst_service();
    DAC8568_DMA_Service();

    TickType_t now = xTaskGetTickCount();
    if ((now - last_log) >= pdMS_TO_TICKS(1000)) {
      uint32_t ok = 0u;
      uint32_t fail = 0u;
      uint32_t skip = 0u;
      uint32_t recover = 0u;
      uint32_t reason = 0u;
      uint32_t ref_rearm = 0u;
      uint32_t ref_refresh = 0u;
      uint32_t stagnant = 0u;
      uint8_t active_source = 0u;
      uint8_t mmap = 0u;
      uint8_t qspi_busy = 0u;
      DAC8568_Aux4Status_t aux4_status;

      DAC8568_DMA_GetStats(&ok, &fail, &skip);
      DAC8568_DMA_GetHealth(&recover, &reason, &ref_rearm, &ref_refresh, &stagnant);
      DAC8568_Aux4_GetStatus(&aux4_status);
      active_source = DAC8568_DMA_GetActiveQspiSource();
      mmap = QSPI_W25Qxx_IsMemoryMapped();
      qspi_busy = QSPI_W25Qxx_IsCommandModeBusy();
      printf("[DAC] ok=%lu fail=%lu skip=%lu rec=%lu reason=%lu ref=%lu refresh=%lu stagnant=%lu ready=0x%02lX sd=0x%02lX boot=%u stream=%u src=%u mmap=%u busy=%u\r\n",
             (unsigned long)ok,
             (unsigned long)fail,
             (unsigned long)skip,
             (unsigned long)recover,
             (unsigned long)reason,
             (unsigned long)ref_rearm,
             (unsigned long)ref_refresh,
             (unsigned long)stagnant,
             (unsigned long)s_dac_wave_ready_mask,
             (unsigned long)s_dac_wave_sd_sync_mask,
             (unsigned)s_dac_wave_boot_sync_done,
             (unsigned)s_dac_stream_started,
             (unsigned)active_source,
             (unsigned)mmap,
             (unsigned)qspi_busy);
      printf("[AUX4] loaded=%u default=%u source=%u gen=%lu checksum=0x%08lX file=%s items=%lu item=%lu inject=%lu parse_error=%lu values_x1000=[%ld,%ld,%ld,%ld] mv=[%ld,%ld,%ld,%ld]\r\n",
             (unsigned)aux4_status.loaded,
             (unsigned)aux4_status.using_default,
             (unsigned)aux4_status.source,
             (unsigned long)aux4_status.generation,
             (unsigned long)aux4_status.payload_checksum,
             aux4_status.active_file,
             (unsigned long)aux4_status.active_item_count,
             (unsigned long)aux4_status.last_item_index,
             (unsigned long)aux4_status.inject_count,
             (unsigned long)aux4_status.parse_error_count,
             (long)dac_aux4_scale1000(aux4_status.values[0]),
             (long)dac_aux4_scale1000(aux4_status.values[1]),
             (long)dac_aux4_scale1000(aux4_status.values[2]),
             (long)dac_aux4_scale1000(aux4_status.values[3]),
             (long)dac_aux4_scale1000(aux4_status.volts[0]),
             (long)dac_aux4_scale1000(aux4_status.volts[1]),
             (long)dac_aux4_scale1000(aux4_status.volts[2]),
             (long)dac_aux4_scale1000(aux4_status.volts[3]));
      printf("[AUX4] range_lo_x1000=[%ld,%ld,%ld,%ld] range_hi_x1000=[%ld,%ld,%ld,%ld] default_x1000=[%ld,%ld,%ld,%ld]\r\n",
             (long)dac_aux4_scale1000(aux4_status.range_lo[0]),
             (long)dac_aux4_scale1000(aux4_status.range_lo[1]),
             (long)dac_aux4_scale1000(aux4_status.range_lo[2]),
             (long)dac_aux4_scale1000(aux4_status.range_lo[3]),
             (long)dac_aux4_scale1000(aux4_status.range_hi[0]),
             (long)dac_aux4_scale1000(aux4_status.range_hi[1]),
             (long)dac_aux4_scale1000(aux4_status.range_hi[2]),
             (long)dac_aux4_scale1000(aux4_status.range_hi[3]),
             (long)dac_aux4_scale1000(aux4_status.default_values[0]),
             (long)dac_aux4_scale1000(aux4_status.default_values[1]),
             (long)dac_aux4_scale1000(aux4_status.default_values[2]),
             (long)dac_aux4_scale1000(aux4_status.default_values[3]));
      last_log = now;
    }

    osDelay(5);
  }
  /* USER CODE END Main_Task */
}

/* USER CODE BEGIN Application */

static uint32_t dac_fault_clamp_duration_s(uint32_t duration_s)
{
  if (duration_s < 1u) {
    return 1u;
  }
  if (duration_s > 3600u) {
    return 3600u;
  }
  return duration_s;
}

static bool dac_wave_partition_ready(uint8_t partition)
{
  if (partition >= DAC_WAVE_PART_COUNT) {
    return false;
  }
  if ((s_dac_wave_ready_mask & (1u << partition)) == 0u) {
    return false;
  }
  if (s_dac_wave_info[partition].qspi_mmap_addr == 0u || s_dac_wave_info[partition].sample_count == 0u) {
    return false;
  }
  return true;
}

static bool dac_wave_accept_partition(uint32_t index, SD_DacWavePartition_t part, const SD_DacWaveInfo_t *info)
{
  uint32_t safe_samples = 0u;

  if ((info == NULL) || (index >= DAC_WAVE_PART_COUNT)) {
    return false;
  }

  safe_samples = DAC8568_DMA_GetQspiSafeSamples(info->qspi_mmap_addr, info->sample_count);
  printf("[DAC WAVE] partition check: code=%s part=%s(%lu) path=%s header_count=%lu safe_samples=%lu checksum=0x%08lX addr=0x%08lX\r\n",
         s_dac_wave_ai_code_by_part[index],
         SD_Wave_GetPartitionName(part),
         (unsigned long)part,
         s_dac_wave_sd_paths[index],
         (unsigned long)info->sample_count,
         (unsigned long)safe_samples,
         (unsigned long)info->checksum,
         (unsigned long)info->qspi_mmap_addr);

  if (safe_samples != info->sample_count) {
    printf("[DAC WAVE] partition rejected: part=%s header_count=%lu safe_samples=%lu\r\n",
           SD_Wave_GetPartitionName(part),
           (unsigned long)info->sample_count,
           (unsigned long)safe_samples);
    return false;
  }

  s_dac_wave_info[index] = *info;
  s_dac_wave_ready_mask |= (1u << index);
  return true;
}

static bool dac_aux4_verify_ready_waves(void)
{
  bool all_verified = true;
  uint32_t ready_count = 0u;
  uint32_t verified_count = 0u;

  for (uint32_t i = 0u; i < DAC_WAVE_PART_COUNT; i++) {
    if ((s_dac_wave_ready_mask & (1u << i)) == 0u) {
      continue;
    }
    ready_count++;
    if (DAC8568_Aux4_VerifyWave((uint8_t)i,
                                s_dac_wave_info[i].sample_rate_hz,
                                s_dac_wave_info[i].sample_count,
                                s_dac_wave_info[i].checksum)) {
      verified_count++;
    } else {
      all_verified = false;
    }
  }
  printf("[AUX4] bind summary: ready=%lu verified=%lu all=%u\r\n",
         (unsigned long)ready_count,
         (unsigned long)verified_count,
         (unsigned)all_verified);
  return (ready_count > 0u) && (verified_count == ready_count);
}

bool DAC_Wave_IsBootReady(void)
{
  return (s_dac_wave_boot_sync_done != 0u) &&
         (s_dac_stream_started != 0u) &&
         dac_wave_partition_ready(0u);
}

static int32_t dac_aux4_scale1000(float value)
{
  if (value >= 0.0f) {
    return (int32_t)(value * 1000.0f + 0.5f);
  }
  return (int32_t)(value * 1000.0f - 0.5f);
}

bool edgewind_ui_can_show_enter_button(void)
{
  return DAC_Wave_IsBootReady();
}

void edgewind_ui_on_before_enter_button(void)
{
  if (!DAC_Wave_IsBootReady()) {
    edgewind_ui_log_set("SD->W25Q waveform sync...");
  }
}

static void dac_fault_queue_reset(void)
{
  uint32_t primask = __get_PRIMASK();

  __disable_irq();
  s_fault_cmd_head = 0u;
  s_fault_cmd_tail = 0u;
  s_fault_cmd_count = 0u;
  if (primask == 0u) {
    __enable_irq();
  }
}

static bool dac_fault_post_command(uint8_t cmd_type, uint8_t fault_id_0_5, uint32_t duration_s)
{
  uint32_t primask = 0u;
  uint8_t tail = 0u;
  bool posted = false;

  if ((cmd_type != DAC_FAULT_CMD_TRIGGER) && (cmd_type != DAC_FAULT_CMD_STOP)) {
    return false;
  }

  primask = __get_PRIMASK();
  __disable_irq();

  if (cmd_type == DAC_FAULT_CMD_STOP) {
    s_fault_cmd_head = 0u;
    s_fault_cmd_tail = 0u;
    s_fault_cmd_count = 0u;
  }

  if (s_fault_cmd_count < DAC_FAULT_CMD_QUEUE_LEN) {
    tail = s_fault_cmd_tail;
    s_fault_cmd_queue[tail].type = cmd_type;
    s_fault_cmd_queue[tail].fault_id_0_5 = fault_id_0_5;
    s_fault_cmd_queue[tail].reserved = 0u;
    s_fault_cmd_queue[tail].duration_s = duration_s;
    tail++;
    if (tail >= DAC_FAULT_CMD_QUEUE_LEN) {
      tail = 0u;
    }
    s_fault_cmd_tail = tail;
    s_fault_cmd_count++;
    posted = true;
  }

  if (primask == 0u) {
    __enable_irq();
  }

  return posted;
}

static bool dac_fault_fetch_command(DacFaultCommand_t *cmd_out)
{
  uint32_t primask = 0u;
  uint8_t head = 0u;
  bool fetched = false;

  if (cmd_out == NULL) {
    return false;
  }

  primask = __get_PRIMASK();
  __disable_irq();
  if (s_fault_cmd_count > 0u) {
    head = s_fault_cmd_head;
    *cmd_out = s_fault_cmd_queue[head];
    head++;
    if (head >= DAC_FAULT_CMD_QUEUE_LEN) {
      head = 0u;
    }
    s_fault_cmd_head = head;
    s_fault_cmd_count--;
    fetched = true;
  }
  if (primask == 0u) {
    __enable_irq();
  }

  return fetched;
}

static uint8_t dac_fault_partition_for_id(uint32_t fault_id_0_5)
{
  if (fault_id_0_5 >= DAC_FAULT_COUNT) {
    return 0xFFu;
  }
  return s_dac_fault_partition_by_id[fault_id_0_5];
}

static bool dac_fault_apply_trigger(uint32_t fault_id_0_5, uint32_t duration_s)
{
  const uint8_t partition = dac_fault_partition_for_id(fault_id_0_5);
  const uint32_t dur_s = dac_fault_clamp_duration_s(duration_s);
  const TickType_t now = xTaskGetTickCount();
  const TickType_t delta = pdMS_TO_TICKS(dur_s * 1000u);
  int32_t req_ret = 0;

  if (partition >= DAC_WAVE_PART_COUNT) {
    printf("[DAC BURST] trigger reject invalid id=%lu\r\n",
           (unsigned long)fault_id_0_5);
    return false;
  }
  if (s_dac_wave_boot_sync_done == 0u || s_dac_stream_started == 0u) {
    printf("[DAC BURST] trigger reject state: id=%lu boot=%u stream=%u ready=0x%02lX\r\n",
           (unsigned long)fault_id_0_5,
           (unsigned)s_dac_wave_boot_sync_done,
           (unsigned)s_dac_stream_started,
           (unsigned long)s_dac_wave_ready_mask);
    return false;
  }
  if (!dac_wave_partition_ready(0u) || !dac_wave_partition_ready(partition)) {
    printf("[DAC BURST] trigger reject wave: id=%lu part=%u ready=0x%02lX normal_addr=0x%08lX fault_addr=0x%08lX\r\n",
           (unsigned long)fault_id_0_5,
           (unsigned)partition,
           (unsigned long)s_dac_wave_ready_mask,
           (unsigned long)s_dac_wave_info[0].qspi_mmap_addr,
           (unsigned long)s_dac_wave_info[partition].qspi_mmap_addr);
    return false;
  }

  req_ret = DAC8568_DMA_RequestQspiWave(partition,
                                        s_dac_wave_info[partition].qspi_mmap_addr,
                                        s_dac_wave_info[partition].sample_count,
                                        true);
  printf("[DAC BURST] request: id=%lu code=%s part=%s(%u) addr=0x%08lX count=%lu checksum=0x%08lX ret=%ld\r\n",
         (unsigned long)fault_id_0_5,
         s_dac_fault_ai_code_by_id[fault_id_0_5],
         SD_Wave_GetPartitionName((SD_DacWavePartition_t)partition),
         (unsigned)partition,
         (unsigned long)s_dac_wave_info[partition].qspi_mmap_addr,
         (unsigned long)s_dac_wave_info[partition].sample_count,
         (unsigned long)s_dac_wave_info[partition].checksum,
         (long)req_ret);
  if (req_ret != 0) {
    return false;
  }

  DAC8568_Aux4_SetActiveFile(s_dac_wave_sd_paths[partition], true);
  s_fault_active_id_0_5 = (uint8_t)fault_id_0_5;
  s_fault_end_tick = now + delta;
  s_fault_remaining_s = dur_s;
  return true;
}

static void dac_fault_apply_stop(void)
{
  int32_t req_ret = 0;

  if (s_dac_wave_boot_sync_done == 0u || s_dac_stream_started == 0u) {
    return;
  }
  if (!dac_wave_partition_ready(0u)) {
    return;
  }

  req_ret = DAC8568_DMA_RequestQspiWave(0u,
                                        s_dac_wave_info[0].qspi_mmap_addr,
                                        s_dac_wave_info[0].sample_count,
                                        false);
  printf("[DAC BURST] baseline request: addr=0x%08lX count=%lu checksum=0x%08lX ret=%ld\r\n",
         (unsigned long)s_dac_wave_info[0].qspi_mmap_addr,
         (unsigned long)s_dac_wave_info[0].sample_count,
         (unsigned long)s_dac_wave_info[0].checksum,
         (long)req_ret);

  if (req_ret == 0) {
    DAC8568_Aux4_SetActiveFile(DAC_WAVE_SD_PATH_NORMAL, false);
  }
  s_fault_active_id_0_5 = 0xFFu;
  s_fault_end_tick = 0;
  s_fault_remaining_s = 0u;
}

bool DAC_FaultBurst_Trigger(uint32_t fault_id_0_5, uint32_t duration_s)
{
  const uint8_t partition = dac_fault_partition_for_id(fault_id_0_5);

  if (partition >= DAC_WAVE_PART_COUNT) {
    return false;
  }
  if (s_dac_wave_boot_sync_done == 0u || s_dac_stream_started == 0u) {
    return false;
  }
  if (!dac_wave_partition_ready(0u) || !dac_wave_partition_ready(partition)) {
    return false;
  }
  if (!dac_fault_post_command(DAC_FAULT_CMD_TRIGGER, (uint8_t)fault_id_0_5, duration_s)) {
    printf("[DAC BURST] command queue full: trigger id=%lu dur=%lus\r\n",
           (unsigned long)fault_id_0_5,
           (unsigned long)duration_s);
    return false;
  }
  return true;
}

uint8_t DAC_FaultBurst_GetPartitionForFaultId(uint32_t fault_id_0_5)
{
  return dac_fault_partition_for_id(fault_id_0_5);
}

bool DAC_FaultBurst_Stop(void)
{
  if (s_dac_wave_boot_sync_done == 0u || s_dac_stream_started == 0u) {
    return false;
  }
  if (!dac_wave_partition_ready(0u)) {
    return false;
  }
  if (!dac_fault_post_command(DAC_FAULT_CMD_STOP, 0xFFu, 0u)) {
    printf("[DAC BURST] command queue full: stop\r\n");
    return false;
  }
  return true;
}

void DAC_FaultBurst_GetUiState(uint32_t *ready_mask, uint8_t *active_fault_id_0_5, uint32_t *remaining_s)
{
  uint32_t ready_snapshot = 0u;
  uint8_t active_snapshot = 0xFFu;
  uint32_t remaining_snapshot = 0u;
  uint32_t primask = __get_PRIMASK();

  __disable_irq();
  ready_snapshot = s_dac_wave_ready_mask;
  active_snapshot = s_fault_active_id_0_5;
  remaining_snapshot = s_fault_remaining_s;
  if (primask == 0u) {
    __enable_irq();
  }

  if (ready_mask != NULL) {
    *ready_mask = ready_snapshot;
  }
  if (active_fault_id_0_5 != NULL) {
    *active_fault_id_0_5 = active_snapshot;
  }
  if (remaining_s != NULL) {
    *remaining_s = remaining_snapshot;
  }
}

static void dac_fault_burst_service(void)
{
  DacFaultCommand_t cmd = {0};

  if (dac_fault_fetch_command(&cmd)) {
    if (cmd.type == DAC_FAULT_CMD_TRIGGER) {
      if (!dac_fault_apply_trigger((uint32_t)cmd.fault_id_0_5, cmd.duration_s)) {
        printf("[DAC BURST] trigger rejected: id=%lu dur=%lus\r\n",
               (unsigned long)cmd.fault_id_0_5,
               (unsigned long)cmd.duration_s);
      } else {
        printf("[DAC BURST] trigger ok: id=%lu dur=%lus\r\n",
               (unsigned long)cmd.fault_id_0_5,
               (unsigned long)dac_fault_clamp_duration_s(cmd.duration_s));
      }
    } else if (cmd.type == DAC_FAULT_CMD_STOP) {
      dac_fault_apply_stop();
      printf("[DAC BURST] stop\r\n");
    }
  }

  if (s_fault_active_id_0_5 == 0xFFu) {
    return;
  }
  TickType_t end = s_fault_end_tick;
  if (end == 0) {
    return;
  }

  TickType_t now = xTaskGetTickCount();
  /* Signed compare handles tick wrap-around. */
  if ((int32_t)(end - now) <= 0) {
    dac_fault_apply_stop();
    return;
  }

  uint32_t remaining_ms = (uint32_t)(end - now) * (uint32_t)portTICK_PERIOD_MS;
  uint32_t remaining_s = (remaining_ms + 999u) / 1000u;
  if (remaining_s != s_fault_remaining_s) {
    s_fault_remaining_s = remaining_s;
  }
}

/* USER CODE END Application */
